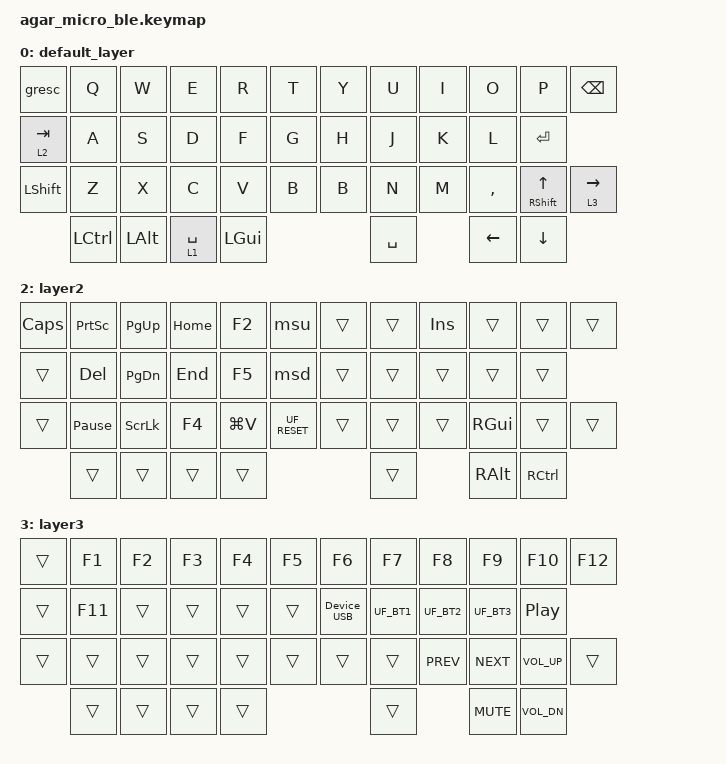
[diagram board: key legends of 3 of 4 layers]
#include "common.keymap"

#define UF_RESET bootloader_reset 0 0
#define UF_BT1 device_bt1 0 0
#define UF_BT2 device_bt2 0 1
#define UF_BT3 device_bt3 0 2

/ {
    keymap {
        compatible = "zmk,keymap";

        default_layer {
            bindings = <
&gresc     &kp Q      &kp W     &kp E  &kp R        &kp T        &kp Y      &kp U  &kp I      &kp O           &kp P                 &kp BSPC
&lt_hp 2 TAB  &kp A      &kp S     &kp D  &kp F        &kp G        &kp H      &kp J  &kp K      &kp L                       &kp RET
&kp LSHFT  &kp Z      &kp X     &kp C  &kp V        &kp B           &kp B   &kp N      &kp M  &kp COMMA      &mt RSHIFT UP_ARROW  &lt_hp 3 RIGHT_ARROW
           &kp LCTRL  &kp LALT         &lt 1 SPACE    &kp LGUI      &kp SPACE                    &kp LEFT_ARROW  &kp DOWN_ARROW
            >;
        };

        layer1 {
            bindings = <
&kp GRAVE  &kp N1  &kp N2  &kp N3  &kp N4  &kp N5               &kp N6            &kp N7             &kp N8  &kp N9     &kp N0            &kp BACKSLASH
&trans     &trans  &trans  &mkp LCLK   &mmu    &mkp RCLK        &kp LEFT_BRACKET  &kp RIGHT_BRACKET  &kp MINUS  &kp EQUAL    &kp SINGLE_QUOTE
&trans     &trans  &trans    &mml      &mmd    &mmr             &trans            &kp SEMI          &kp DOT  &kp SLASH  &trans    &trans
           &trans  &trans                  &trans                           &trans                                 &trans     &trans
            >;
        };

        layer2 {
            bindings = <
&kp CAPSLOCK  &kp PRINTSCREEN  &kp PAGE_UP     &kp HOME  &kp F2     &msu        &trans  &trans  &kp INSERT  &trans    &trans     &trans
&trans        &kp DELETE       &kp PAGE_DOWN   &kp END   &kp F5     &msd        &trans  &trans  &trans      &trans         &trans
&trans        &kp PAUSE_BREAK  &kp SCROLLLOCK  &kp F4    &kp LG(V)  &UF_RESET    &trans  &trans  &trans      &kp RGUI  &trans     &trans
              &trans           &trans     &trans  &trans                             &trans                      &kp RALT  &kp RCTRL
            >;
        };

        layer3 {
            bindings = <
&trans  &kp F1  &kp F2  &kp F3  &kp F4  &kp F5          &kp F6  &kp F7  &kp F8      &kp F9      &kp F10                 &kp F12
&trans  &kp F11 &trans  &trans  &trans  &trans          &Device_USB  &UF_BT1  &UF_BT2  &UF_BT3   &kp C_PLAY_PAUSE
&trans  &trans  &trans  &trans  &trans  &trans          &trans  &trans  &kp C_PREV  &kp C_NEXT  &kp C_VOL_UP  &trans
        &trans  &trans          &trans  &trans                      &trans                      &kp C_MUTE  &kp C_VOL_DN
            >;
        };

        layer4 { status = "reserved"; };
        layer5 { status = "reserved"; };
        layer6 { status = "reserved"; };
        layer7 { status = "reserved"; };

    };
};
